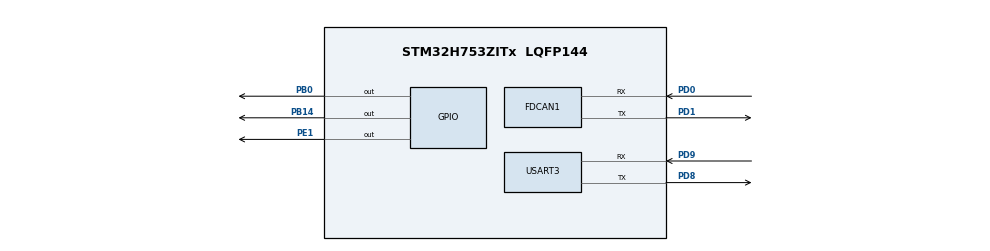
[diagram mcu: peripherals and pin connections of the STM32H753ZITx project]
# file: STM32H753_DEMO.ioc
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CORTEX_M7.default_mode_Activation=1
FDCAN1.CalculateBaudRateNominal=499999
FDCAN1.CalculateTimeBitNominal=2000
FDCAN1.CalculateTimeQuantumNominal=83.33333333333334
FDCAN1.DataPrescaler=10
FDCAN1.DataSyncJumpWidth=3
FDCAN1.DataTimeSeg1=20
FDCAN1.DataTimeSeg2=3
FDCAN1.NominalPrescaler=10
FDCAN1.NominalSyncJumpWidth=3
FDCAN1.NominalTimeSeg1=20
FDCAN1.NominalTimeSeg2=3
FDCAN1.ProtocolException=ENABLE
FDCAN1.RxFifo0ElmtsNbr=20
FDCAN1.StdFiltersNbr=1
FDCAN1.TxFifoQueueElmtsNbr=20
Mcu.Family=STM32H7
Mcu.Name=STM32H753ZITx
Mcu.Package=LQFP144
NVIC.FDCAN1_IT0_IRQn=true\:0\:0\:false\:false\:true\:true\:true\:true
NVIC.PriorityGroup=NVIC_PRIORITYGROUP_4
NVIC.USART3_IRQn=true\:0\:0\:false\:false\:true\:true\:true\:true
PB0.Signal=GPIO_Output
PB14.Signal=GPIO_Output
PD0.Mode=FDCAN_Activate
PD0.Signal=FDCAN1_RX
PD1.Mode=FDCAN_Activate
PD1.Signal=FDCAN1_TX
PD8.Mode=Asynchronous
PD8.Signal=USART3_TX
PD9.Mode=Asynchronous
PD9.Signal=USART3_RX
PE1.Signal=GPIO_Output
PH0-OSC_IN\ (PH0).Mode=HSE-External-Oscillator
PH0-OSC_IN\ (PH0).Signal=RCC_OSC_IN
PH1-OSC_OUT\ (PH1).Mode=HSE-External-Oscillator
PH1-OSC_OUT\ (PH1).Signal=RCC_OSC_OUT
ProjectManager.HeapSize=0x200
ProjectManager.StackSize=0x400
ProjectManager.TargetToolchain=STM32CubeIDE
RCC.ADCFreq_Value=240000000
RCC.APB1Freq_Value=120000000
RCC.APB2Freq_Value=120000000
RCC.APB3Freq_Value=120000000
RCC.APB4Freq_Value=120000000
RCC.CortexFreq_Value=480000000
RCC.D1PPRE=RCC_APB3_DIV2
RCC.D2PPRE1=RCC_APB1_DIV2
RCC.D2PPRE2=RCC_APB2_DIV2
RCC.D3PPRE=RCC_APB4_DIV2
RCC.DIVM1=2
RCC.DIVM2=4
RCC.DIVM3=4
RCC.DIVN1=240
RCC.DIVN2=240
RCC.DIVN3=144
RCC.DIVQ2=4
RCC.DIVQ3=6
RCC.FDCANCLockSelection=RCC_FDCANCLKSOURCE_PLL2
RCC.HCLKFreq_Value=240000000
RCC.HPRE=RCC_HCLK_DIV2
RCC.HSE_VALUE=8000000
RCC.PLLSourceVirtual=RCC_PLLSOURCE_HSE
RCC.SYSCLKFreq_VALUE=480000000
RCC.SYSCLKSource=RCC_SYSCLKSOURCE_PLLCLK
RCC.USBFreq_Value=480000000
USART3.VirtualMode-Asynchronous=VM_ASYNC
VP_MEMORYMAP_VS_MEMORYMAP.Mode=CurAppReg
board=custom

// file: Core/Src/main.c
/* USER CODE BEGIN Header */
/**
  ******************************************************************************
  * @file           : main.c
  * @brief          : Main program body
  ******************************************************************************
  * @attention
  *
  * Copyright (c) 2025 STMicroelectronics.
  * All rights reserved.
  *
  * This software is licensed under terms that can be found in the LICENSE file
  * in the root directory of this software component.
  * If no LICENSE file comes with this software, it is provided AS-IS.
  *
  ******************************************************************************
  */
/* USER CODE END Header */
#include "main.h"
#include "fdcan.h"
#include "usart.h"
#include "gpio.h"

/* USER CODE BEGIN Includes */
#include "board.h"
/* USER CODE END Includes */

void SystemClock_Config(void);
static void MPU_Config(void);

int main(void)
{

  /* MPU Configuration--------------------------------------------------------*/
  MPU_Config();

  /* MCU Configuration--------------------------------------------------------*/

  /* Reset of all peripherals, Initializes the Flash interface and the Systick. */
  HAL_Init();

  /* Configure the system clock */
  SystemClock_Config();

  /* Initialize all configured peripherals */
  MX_GPIO_Init();
  MX_USART3_UART_Init();
  MX_FDCAN1_Init();

  /* Infinite loop */
  while (1)
  {

    /* USER CODE BEGIN 3 */
    report_board_version();
    flash_heartbeat();
    HAL_Delay(1000);
  }
  /* USER CODE END 3 */
}

void SystemClock_Config(void)
{
  RCC_OscInitTypeDef RCC_OscInitStruct = {0};
  RCC_ClkInitTypeDef RCC_ClkInitStruct = {0};

  /** Supply configuration update enable
  */
  HAL_PWREx_ConfigSupply(PWR_LDO_SUPPLY);

  /** Configure the main internal regulator output voltage
  */
  __HAL_PWR_VOLTAGESCALING_CONFIG(PWR_REGULATOR_VOLTAGE_SCALE0);

  while(!__HAL_PWR_GET_FLAG(PWR_FLAG_VOSRDY)) {}

  /** Initializes the RCC Oscillators according to the specified parameters
  * in the RCC_OscInitTypeDef structure.
  */
  RCC_OscInitStruct.OscillatorType = RCC_OSCILLATORTYPE_HSE;
  RCC_OscInitStruct.HSEState = RCC_HSE_ON;
  RCC_OscInitStruct.PLL.PLLState = RCC_PLL_ON;
  RCC_OscInitStruct.PLL.PLLSource = RCC_PLLSOURCE_HSE;
  RCC_OscInitStruct.PLL.PLLM = 2;
  RCC_OscInitStruct.PLL.PLLN = 240;
  RCC_OscInitStruct.PLL.PLLP = 2;
  RCC_OscInitStruct.PLL.PLLQ = 2;
  RCC_OscInitStruct.PLL.PLLR = 2;
  RCC_OscInitStruct.PLL.PLLRGE = RCC_PLL1VCIRANGE_2;
  RCC_OscInitStruct.PLL.PLLVCOSEL = RCC_PLL1VCOWIDE;
  RCC_OscInitStruct.PLL.PLLFRACN = 0;
  if (HAL_RCC_OscConfig(&RCC_OscInitStruct) != HAL_OK)
  {
    Error_Handler();
  }

  /** Initializes the CPU, AHB and APB buses clocks
  */
  RCC_ClkInitStruct.ClockType = RCC_CLOCKTYPE_HCLK|RCC_CLOCKTYPE_SYSCLK
                              |RCC_CLOCKTYPE_PCLK1|RCC_CLOCKTYPE_PCLK2
                              |RCC_CLOCKTYPE_D3PCLK1|RCC_CLOCKTYPE_D1PCLK1;
  RCC_ClkInitStruct.SYSCLKSource = RCC_SYSCLKSOURCE_PLLCLK;
  RCC_ClkInitStruct.SYSCLKDivider = RCC_SYSCLK_DIV1;
  RCC_ClkInitStruct.AHBCLKDivider = RCC_HCLK_DIV2;
  RCC_ClkInitStruct.APB3CLKDivider = RCC_APB3_DIV2;
  RCC_ClkInitStruct.APB1CLKDivider = RCC_APB1_DIV2;
  RCC_ClkInitStruct.APB2CLKDivider = RCC_APB2_DIV2;
  RCC_ClkInitStruct.APB4CLKDivider = RCC_APB4_DIV2;

  if (HAL_RCC_ClockConfig(&RCC_ClkInitStruct, FLASH_LATENCY_4) != HAL_OK)
  {
    Error_Handler();
  }
}

 /* MPU Configuration */

void MPU_Config(void)
{
  MPU_Region_InitTypeDef MPU_InitStruct = {0};

  /* Disables the MPU */
  HAL_MPU_Disable();

  /** Initializes and configures the Region and the memory to be protected
  */
  MPU_InitStruct.Enable = MPU_REGION_ENABLE;
  MPU_InitStruct.Number = MPU_REGION_NUMBER0;
  MPU_InitStruct.BaseAddress = 0x0;
  MPU_InitStruct.Size = MPU_REGION_SIZE_4GB;
  MPU_InitStruct.SubRegionDisable = 0x87;
  MPU_InitStruct.TypeExtField = MPU_TEX_LEVEL0;
  MPU_InitStruct.AccessPermission = MPU_REGION_NO_ACCESS;
  MPU_InitStruct.DisableExec = MPU_INSTRUCTION_ACCESS_DISABLE;
  MPU_InitStruct.IsShareable = MPU_ACCESS_SHAREABLE;
  MPU_InitStruct.IsCacheable = MPU_ACCESS_NOT_CACHEABLE;
  MPU_InitStruct.IsBufferable = MPU_ACCESS_NOT_BUFFERABLE;

  HAL_MPU_ConfigRegion(&MPU_InitStruct);
  /* Enables the MPU */
  HAL_MPU_Enable(MPU_PRIVILEGED_DEFAULT);

}

void Error_Handler(void)
{
  __disable_irq();
  while (1)
  {
  }
}
